AUTOSAR XML (schema 00049)
standard types defined: boolean, float32, float64, sint16, uint16, uint8, boolean_CompuMethod, boolean_DataConstr, float32_DataConstr, float64_DataConstr, sint16_DataConstr, uint16_DataConstr, uint8_DataConstr
package /AUTOSAR_Platform/ImplementationDataTypes/SwAddrMethods
  sw addr method ASW_Variables: memory-allocation-keyword-policy=ADDR-METHOD-SHORT-NAME, section-initialization-policy=INIT, section-type=VAR
  sw addr method CODE: memory-allocation-keyword-policy=ADDR-METHOD-SHORT-NAME, section-type=CODE
package /AUTOSAR_Platform/ImplementationDataTypes/Units
  unit NoUnit: factor-si-to-unit=1, offset-si-to-unit=0
package /ComponentTypes
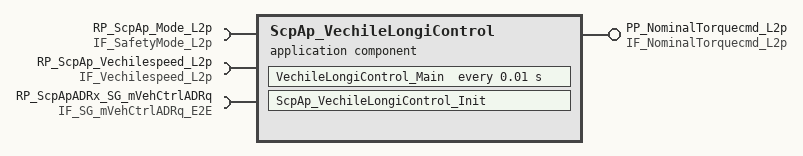
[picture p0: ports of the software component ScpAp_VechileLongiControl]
  application sw component type ScpAp_VechileLongiControl
    require port RP_ScpAp_Mode_L2p: nonqueued-receiver-com-spec{data-element=IF_SafetyMode_L2p, init-value=AUTONOMOUS}, required-interface=IF_SafetyMode_L2p
    require port RP_ScpAp_Vechilespeed_L2p: nonqueued-receiver-com-spec{data-element=IF_Vechilespeed_L2p, init-value=0}, required-interface=IF_Vechilespeed_L2p
    require port RP_ScpApADRx_SG_mVehCtrlADRq: nonqueued-receiver-com-spec{data-element=SG_mVehCtrlADRq, init-value={short-label=ComSpec64bb04c2_01277ab3d6cb378d, fields=[AebEvent:0, AebSrcAD:0, b_High_Deceleration_Flag:0, MsgCntrmVehCtrlADRq:0, MsgCrc_mVehCtrlADRq:0, VehAccelLongCmd:0, VehDirCmd:0, VehRoadWhlAngleCmd:0, VehSpdCmd:0, CanAd78FltCod:0]}}, required-interface=IF_SG_mVehCtrlADRq_E2E
    provide port PP_NominalTorquecmd_L2p: nonqueued-sender-com-spec{data-element=IF_NominalTorquecmd_L2p, init-value=ComSpecb4e9f174_e3823742572cf280:0}, provided-interface=IF_NominalTorquecmd_L2p
    behavior ScpAp_VechileLongiControl_InternalBehavior: handle-termination-and-restart=NO-SUPPORT
      static-memorys:
        8 x data, all with category=VALUE, sw-addr-method=ASW_Variables, sw-calibration-access=READ-ONLY:
          Integrator_State: type=float64
          ScpAp_VechileLong_VehSpdCmd_Kph: type=float32
          ScpAp_VechileLongiC_Speed_Error: type=float32
          ScpAp_Vech_NominalTorquecmd_L2p: type=sint16
          ScpAp_Clamped_Integrator_State: type=sint16
          ScpAp_Vechile_proportional_term: type=sint16
          ScpAp_VechileLongiC_Control_raw: type=sint16
          ScpAp_Cal_NominalTorquecmd_L2p: type=sint16
      timing event TMT_VechileLongiControl_Main: start-on-event=VechileLongiControl_Main, period=0.01
      runnable ScpAp_VechileLongiControl_Init: sw-addr-method=CODE
      runnable VechileLongiControl_Main: sw-addr-method=CODE
        data-receive-point-by-arguments:
          access IN_RP_ScpAp_Mode_L2p_IF_SafetyMode_L2p: accessed-variable=RP_ScpAp_Mode_L2p.IF_SafetyMode_L2p
          access IN_RP_ScpAp_Vechilespeed_L2p_IF_Vechilespeed_L2p: accessed-variable=RP_ScpAp_Vechilespeed_L2p.IF_Vechilespeed_L2p
          access IN_RP_ScpApADRx_SG_mVehCtrlADRq_SG_mVehCtrlADRq: accessed-variable=RP_ScpApADRx_SG_mVehCtrlADRq.SG_mVehCtrlADRq
        data-send-points:
          access OUT_PP_NominalTorquecmd_L2p_IF_NominalTorquecmd_L2p: accessed-variable=PP_NominalTorquecmd_L2p.IF_NominalTorquecmd_L2p
package /DataTypes
  impl type SG_mVehCtrlADRq_IDT_E2E: category=STRUCTURE
    10 x element, all with category=TYPE_REFERENCE:
      AebEvent: implementation-data-type=boolean
      AebSrcAD: implementation-data-type=uint8
      b_High_Deceleration_Flag: implementation-data-type=boolean
      MsgCntrmVehCtrlADRq: implementation-data-type=uint8
      MsgCrc_mVehCtrlADRq: implementation-data-type=uint8
      VehAccelLongCmd: implementation-data-type=float32
      VehDirCmd: implementation-data-type=uint8
      VehRoadWhlAngleCmd: implementation-data-type=float32
      VehSpdCmd: implementation-data-type=float32
      CanAd78FltCod: implementation-data-type=uint8
  impl type SafetyMode_L2p_IDT: category=VALUE, base-type=BaseTypes/uint8, compu {1=AUTONOMOUS, 0=MANUAL, 3=TELEOPS}, range raw 0..255
package /PortInterfaces
  4 x sender receiver interface:
    IF_NominalTorquecmd_L2p: invalidation-policy{data-element=IF_NominalTorquecmd_L2p, handle-invalid=DONT-INVALIDATE}
      data IF_NominalTorquecmd_L2p: category=VALUE, sw-calibration-access=READ-ONLY, type=sint16
    IF_SafetyMode_L2p: invalidation-policy{data-element=IF_SafetyMode_L2p, handle-invalid=DONT-INVALIDATE}
      data IF_SafetyMode_L2p: category=VALUE, sw-calibration-access=READ-ONLY, type=SafetyMode_L2p_IDT
    IF_SG_mVehCtrlADRq_E2E: invalidation-policy{data-element=SG_mVehCtrlADRq, handle-invalid=DONT-INVALIDATE}
      data SG_mVehCtrlADRq: category=STRUCTURE, sw-calibration-access=READ-ONLY, type=SG_mVehCtrlADRq_IDT_E2E
    IF_Vechilespeed_L2p: invalidation-policy{data-element=IF_Vechilespeed_L2p, handle-invalid=DONT-INVALIDATE}
      data IF_Vechilespeed_L2p: category=VALUE, sw-calibration-access=READ-ONLY, type=uint16
